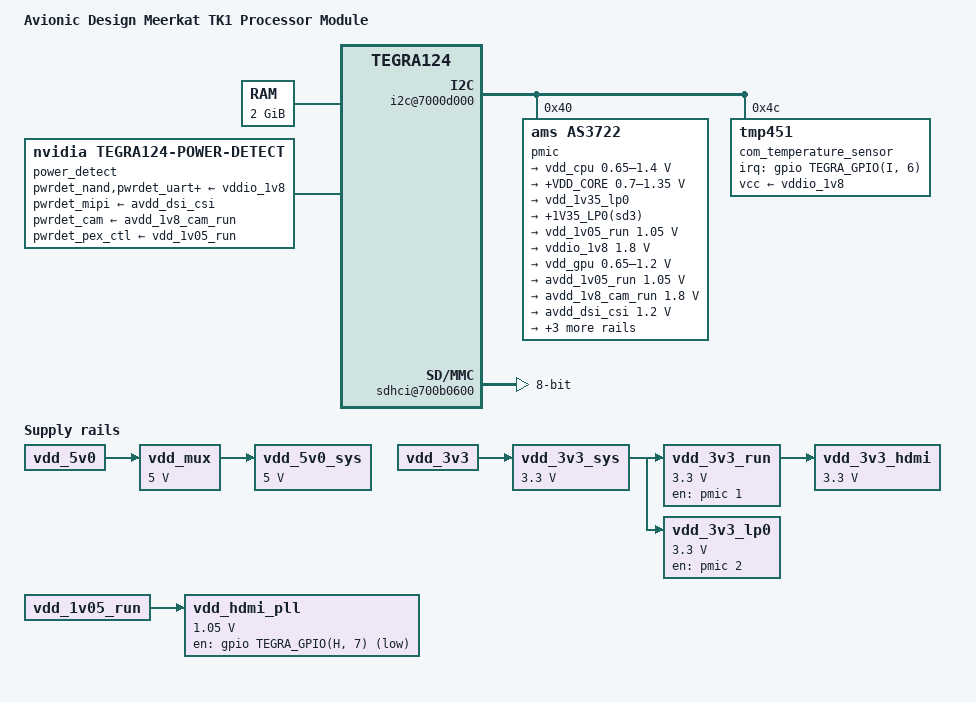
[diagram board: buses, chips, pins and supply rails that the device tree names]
#include <dt-bindings/pinctrl/pinctrl-tegra.h>
#include <dt-bindings/display/tegra-dc.h>
#include <dt-bindings/thermal/thermal.h>
#include <dt-bindings/usb/tegra-ehci.h>
#include <dt-bindings/usb/tegra-xhci.h>
#include <dt-bindings/pci/tegra-pcie.h>
#include <dt-bindings/mfd/as3722.h>
#include "tegra124.dtsi"

/ {
	model = "Avionic Design Meerkat TK1 Processor Module";
	compatible = "ad,meerkat", "nvidia,tegra124";

	aliases {
		rtc0 = "/i2c@7000d000/pmic@40";
		rtc1 = "/rtc@7000e000";
	};

	memory {
		device_type = "memory";
		reg = <0x0 0x80000000 0x0 0x80000000>;
	};

	psci {
		status = "disabled";
	};

	pmu {
		status = "okay";
	};

	pinmux {
		pinctrl-names = "default";
		pinctrl-0 = <&pinmux_default>;

		pinmux_default: common {
			dap_mclk1_pw4 {
				nvidia,pins = "dap_mclk1_pw4";
				nvidia,function = "extperiph1";
				nvidia,enable-input = <TEGRA_PIN_DISABLE>;
				nvidia,pull = <TEGRA_PIN_PULL_NONE>;
				nvidia,tristate = <TEGRA_PIN_DISABLE>;
			};

			dap_mclk1_req_pee2 {
				nvidia,pins = "dap_mclk1_req_pee2";
				nvidia,function = "sata";
				nvidia,enable-input = <TEGRA_PIN_DISABLE>;
				nvidia,pull = <TEGRA_PIN_PULL_NONE>;
				nvidia,tristate = <TEGRA_PIN_DISABLE>;
			};

			dap1_din_pn1 {
				nvidia,pins = "dap1_din_pn1";
				nvidia,function = "i2s0";
				nvidia,enable-input = <TEGRA_PIN_ENABLE>;
				nvidia,pull = <TEGRA_PIN_PULL_DOWN>;
				nvidia,tristate = <TEGRA_PIN_ENABLE>;
			};

			dap1_dout_pn2 {
				nvidia,pins = "dap1_dout_pn2";
				nvidia,function = "sata";
				nvidia,enable-input = <TEGRA_PIN_DISABLE>;
				nvidia,pull = <TEGRA_PIN_PULL_NONE>;
				nvidia,tristate = <TEGRA_PIN_DISABLE>;
			};

			dap1_fs_pn0 {
				nvidia,pins = "dap1_fs_pn0";
				nvidia,function = "i2s0";
				nvidia,enable-input = <TEGRA_PIN_ENABLE>;
				nvidia,pull = <TEGRA_PIN_PULL_DOWN>;
				nvidia,tristate = <TEGRA_PIN_ENABLE>;
			};

			dap1_sclk_pn3 {
				nvidia,pins = "dap1_sclk_pn3";
				nvidia,function = "i2s0";
				nvidia,enable-input = <TEGRA_PIN_ENABLE>;
				nvidia,pull = <TEGRA_PIN_PULL_DOWN>;
				nvidia,tristate = <TEGRA_PIN_ENABLE>;
			};

			dap2_din_pa4 {
				nvidia,pins = "dap2_din_pa4";
				nvidia,function = "i2s1";
				nvidia,enable-input = <TEGRA_PIN_ENABLE>;
				nvidia,pull = <TEGRA_PIN_PULL_NONE>;
				nvidia,tristate = <TEGRA_PIN_ENABLE>;
			};

			dap2_dout_pa5 {
				nvidia,pins = "dap2_dout_pa5";
				nvidia,function = "i2s1";
				nvidia,enable-input = <TEGRA_PIN_ENABLE>;
				nvidia,pull = <TEGRA_PIN_PULL_NONE>;
				nvidia,tristate = <TEGRA_PIN_ENABLE>;
			};

			dap2_fs_pa2 {
				nvidia,pins = "dap2_fs_pa2";
				nvidia,function = "i2s1";
				nvidia,enable-input = <TEGRA_PIN_ENABLE>;
				nvidia,pull = <TEGRA_PIN_PULL_NONE>;
				nvidia,tristate = <TEGRA_PIN_ENABLE>;
			};

			dap2_sclk_pa3 {
				nvidia,pins = "dap2_sclk_pa3";
				nvidia,function = "i2s1";
				nvidia,enable-input = <TEGRA_PIN_ENABLE>;
				nvidia,pull = <TEGRA_PIN_PULL_NONE>;
				nvidia,tristate = <TEGRA_PIN_ENABLE>;
			};

			dvfs_pwm_px0 {
				nvidia,pins = "dvfs_pwm_px0";
				nvidia,function = "cldvfs";
				nvidia,enable-input = <TEGRA_PIN_DISABLE>;
				nvidia,pull = <TEGRA_PIN_PULL_NONE>;
				nvidia,tristate = <TEGRA_PIN_DISABLE>;
			};

			dvfs_clk_px2 {
				nvidia,pins = "dvfs_clk_px2";
				nvidia,function = "cldvfs";
				nvidia,enable-input = <TEGRA_PIN_DISABLE>;
				nvidia,pull = <TEGRA_PIN_PULL_NONE>;
				nvidia,tristate = <TEGRA_PIN_DISABLE>;
			};

			ulpi_clk_py0 {
				nvidia,pins = "ulpi_clk_py0";
				nvidia,function = "spi1";
				nvidia,enable-input = <TEGRA_PIN_DISABLE>;
				nvidia,pull = <TEGRA_PIN_PULL_NONE>;
				nvidia,tristate = <TEGRA_PIN_DISABLE>;
			};

			ulpi_dir_py1 {
				nvidia,pins = "ulpi_dir_py1";
				nvidia,function = "spi1";
				nvidia,enable-input = <TEGRA_PIN_ENABLE>;
				nvidia,pull = <TEGRA_PIN_PULL_NONE>;
				nvidia,tristate = <TEGRA_PIN_DISABLE>;
			};

			ulpi_nxt_py2 {
				nvidia,pins = "ulpi_nxt_py2";
				nvidia,function = "spi1";
				nvidia,enable-input = <TEGRA_PIN_DISABLE>;
				nvidia,pull = <TEGRA_PIN_PULL_NONE>;
				nvidia,tristate = <TEGRA_PIN_DISABLE>;
			};

			ulpi_stp_py3 {
				nvidia,pins = "ulpi_stp_py3";
				nvidia,function = "spi1";
				nvidia,enable-input = <TEGRA_PIN_DISABLE>;
				nvidia,pull = <TEGRA_PIN_PULL_UP>;
				nvidia,tristate = <TEGRA_PIN_DISABLE>;
			};

			cam_i2c_scl_pbb1 {
				nvidia,pins = "cam_i2c_scl_pbb1";
				nvidia,function = "i2c3";
				nvidia,enable-input = <TEGRA_PIN_ENABLE>;
				nvidia,pull = <TEGRA_PIN_PULL_NONE>;
				nvidia,tristate = <TEGRA_PIN_DISABLE>;
				nvidia,lock = <TEGRA_PIN_DISABLE>;
				nvidia,open-drain = <TEGRA_PIN_ENABLE>;
			};

			cam_i2c_sda_pbb2 {
				nvidia,pins = "cam_i2c_sda_pbb2";
				nvidia,function = "i2c3";
				nvidia,enable-input = <TEGRA_PIN_ENABLE>;
				nvidia,pull = <TEGRA_PIN_PULL_NONE>;
				nvidia,tristate = <TEGRA_PIN_DISABLE>;
				nvidia,lock = <TEGRA_PIN_DISABLE>;
				nvidia,open-drain = <TEGRA_PIN_ENABLE>;
			};

			cam_mclk_pcc0 {
				nvidia,pins = "cam_mclk_pcc0";
				nvidia,function = "vi_alt3";
				nvidia,enable-input = <TEGRA_PIN_DISABLE>;
				nvidia,pull = <TEGRA_PIN_PULL_NONE>;
				nvidia,tristate = <TEGRA_PIN_DISABLE>;
			};

			pbb0 {
				nvidia,pins = "pbb0";
				nvidia,function = "vimclk2_alt";
				nvidia,enable-input = <TEGRA_PIN_DISABLE>;
				nvidia,pull = <TEGRA_PIN_PULL_NONE>;
				nvidia,tristate = <TEGRA_PIN_DISABLE>;
			};

			pbb4 {
				nvidia,pins = "pbb4";
				nvidia,function = "vgp4";
				nvidia,enable-input = <TEGRA_PIN_DISABLE>;
				nvidia,pull = <TEGRA_PIN_PULL_NONE>;
				nvidia,tristate = <TEGRA_PIN_DISABLE>;
			};

			gen2_i2c_scl_pt5 {
				nvidia,pins = "gen2_i2c_scl_pt5";
				nvidia,function = "i2c2";
				nvidia,enable-input = <TEGRA_PIN_ENABLE>;
				nvidia,pull = <TEGRA_PIN_PULL_NONE>;
				nvidia,tristate = <TEGRA_PIN_DISABLE>;
				nvidia,lock = <TEGRA_PIN_DISABLE>;
				nvidia,open-drain = <TEGRA_PIN_ENABLE>;
			};

			gen2_i2c_sda_pt6 {
				nvidia,pins = "gen2_i2c_sda_pt6";
				nvidia,function = "i2c2";
				nvidia,enable-input = <TEGRA_PIN_ENABLE>;
				nvidia,pull = <TEGRA_PIN_PULL_NONE>;
				nvidia,tristate = <TEGRA_PIN_DISABLE>;
				nvidia,lock = <TEGRA_PIN_DISABLE>;
				nvidia,open-drain = <TEGRA_PIN_ENABLE>;
			};

			pj7 {
				nvidia,pins = "pj7";
				nvidia,function = "uartd";
				nvidia,enable-input = <TEGRA_PIN_DISABLE>;
				nvidia,pull = <TEGRA_PIN_PULL_NONE>;
				nvidia,tristate = <TEGRA_PIN_DISABLE>;
			};

			pb0 {
				nvidia,pins = "pb0";
				nvidia,function = "uartd";
				nvidia,enable-input = <TEGRA_PIN_ENABLE>;
				nvidia,pull = <TEGRA_PIN_PULL_UP>;
				nvidia,tristate = <TEGRA_PIN_DISABLE>;
			};

			pb1 {
				nvidia,pins = "pb1";
				nvidia,function = "uartd";
				nvidia,enable-input = <TEGRA_PIN_ENABLE>;
				nvidia,pull = <TEGRA_PIN_PULL_UP>;
				nvidia,tristate = <TEGRA_PIN_DISABLE>;
			};

			pk7 {
				nvidia,pins = "pk7";
				nvidia,function = "uartd";
				nvidia,enable-input = <TEGRA_PIN_DISABLE>;
				nvidia,pull = <TEGRA_PIN_PULL_NONE>;
				nvidia,tristate = <TEGRA_PIN_DISABLE>;
			};

			pg4 {
				nvidia,pins = "pg4";
				nvidia,function = "spi4";
				nvidia,enable-input = <TEGRA_PIN_DISABLE>;
				nvidia,pull = <TEGRA_PIN_PULL_UP>;
				nvidia,tristate = <TEGRA_PIN_ENABLE>;
			};

			pg5 {
				nvidia,pins = "pg5";
				nvidia,function = "spi4";
				nvidia,enable-input = <TEGRA_PIN_DISABLE>;
				nvidia,pull = <TEGRA_PIN_PULL_NONE>;
				nvidia,tristate = <TEGRA_PIN_DISABLE>;
			};

			pg6 {
				nvidia,pins = "pg6";
				nvidia,function = "spi4";
				nvidia,enable-input = <TEGRA_PIN_DISABLE>;
				nvidia,pull = <TEGRA_PIN_PULL_NONE>;
				nvidia,tristate = <TEGRA_PIN_DISABLE>;
			};

			pg7 {
				nvidia,pins = "pg7";
				nvidia,function = "spi4";
				nvidia,enable-input = <TEGRA_PIN_ENABLE>;
				nvidia,pull = <TEGRA_PIN_PULL_NONE>;
				nvidia,tristate = <TEGRA_PIN_DISABLE>;
			};

			pi3 {
				nvidia,pins = "pi3";
				nvidia,function = "spi4";
				nvidia,enable-input = <TEGRA_PIN_DISABLE>;
				nvidia,pull = <TEGRA_PIN_PULL_UP>;
				nvidia,tristate = <TEGRA_PIN_DISABLE>;
			};

			ph1 {
				nvidia,pins = "ph1";
				nvidia,function = "pwm1";
				nvidia,enable-input = <TEGRA_PIN_DISABLE>;
				nvidia,pull = <TEGRA_PIN_PULL_NONE>;
				nvidia,tristate = <TEGRA_PIN_DISABLE>;
			};

			pk0 {
				nvidia,pins = "pk0";
				nvidia,function = "soc";
				nvidia,enable-input = <TEGRA_PIN_ENABLE>;
				nvidia,pull = <TEGRA_PIN_PULL_UP>;
				nvidia,tristate = <TEGRA_PIN_ENABLE>;
			};

			kb_row15_ps7 {
				nvidia,pins = "kb_row15_ps7";
				nvidia,function = "soc";
				nvidia,enable-input = <TEGRA_PIN_ENABLE>;
				nvidia,pull = <TEGRA_PIN_PULL_UP>;
				nvidia,tristate = <TEGRA_PIN_DISABLE>;
			};

			clk_32k_out_pa0 {
				nvidia,pins = "clk_32k_out_pa0";
				nvidia,function = "soc";
				nvidia,enable-input = <TEGRA_PIN_ENABLE>;
				nvidia,pull = <TEGRA_PIN_PULL_UP>;
				nvidia,tristate = <TEGRA_PIN_DISABLE>;
			};

			pex_l0_clkreq_n_pdd2 {
				nvidia,pins = "pex_l0_clkreq_n_pdd2";
				nvidia,function = "pe0";
				nvidia,enable-input = <TEGRA_PIN_ENABLE>;
				nvidia,pull = <TEGRA_PIN_PULL_UP>;
				nvidia,tristate = <TEGRA_PIN_DISABLE>;
			};

			pex_l0_rst_n_pdd1 {
				nvidia,pins = "pex_l0_rst_n_pdd1";
				nvidia,function = "pe0";
				nvidia,enable-input = <TEGRA_PIN_DISABLE>;
				nvidia,pull = <TEGRA_PIN_PULL_NONE>;
				nvidia,tristate = <TEGRA_PIN_DISABLE>;
			};

			pex_l1_rst_n_pdd5 {
				nvidia,pins = "pex_l1_rst_n_pdd5";
				nvidia,function = "pe1";
				nvidia,enable-input = <TEGRA_PIN_DISABLE>;
				nvidia,pull = <TEGRA_PIN_PULL_NONE>;
				nvidia,tristate = <TEGRA_PIN_DISABLE>;
			};

			pex_l1_clkreq_n_pdd6 {
				nvidia,pins = "pex_l1_clkreq_n_pdd6";
				nvidia,function = "pe1";
				nvidia,enable-input = <TEGRA_PIN_ENABLE>;
				nvidia,pull = <TEGRA_PIN_PULL_UP>;
				nvidia,tristate = <TEGRA_PIN_DISABLE>;
			};

			pex_wake_n_pdd3 {
				nvidia,pins = "pex_wake_n_pdd3";
				nvidia,function = "pe";
				nvidia,enable-input = <TEGRA_PIN_ENABLE>;
				nvidia,pull = <TEGRA_PIN_PULL_UP>;
				nvidia,tristate = <TEGRA_PIN_DISABLE>;
			};

			sdmmc1_clk_pz0 {
				nvidia,pins = "sdmmc1_clk_pz0";
				nvidia,function = "sdmmc1";
				nvidia,enable-input = <TEGRA_PIN_ENABLE>;
				nvidia,pull = <TEGRA_PIN_PULL_NONE>;
				nvidia,tristate = <TEGRA_PIN_ENABLE>;
			};

			sdmmc1_cmd_pz1 {
				nvidia,pins = "sdmmc1_cmd_pz1";
				nvidia,function = "sdmmc1";
				nvidia,enable-input = <TEGRA_PIN_ENABLE>;
				nvidia,pull = <TEGRA_PIN_PULL_UP>;
				nvidia,tristate = <TEGRA_PIN_ENABLE>;
			};

			sdmmc1_dat0_py7 {
				nvidia,pins = "sdmmc1_dat0_py7";
				nvidia,function = "sdmmc1";
				nvidia,enable-input = <TEGRA_PIN_ENABLE>;
				nvidia,pull = <TEGRA_PIN_PULL_UP>;
				nvidia,tristate = <TEGRA_PIN_ENABLE>;
			};

			sdmmc1_dat1_py6 {
				nvidia,pins = "sdmmc1_dat1_py6";
				nvidia,function = "sdmmc1";
				nvidia,enable-input = <TEGRA_PIN_ENABLE>;
				nvidia,pull = <TEGRA_PIN_PULL_UP>;
				nvidia,tristate = <TEGRA_PIN_ENABLE>;
			};

			sdmmc1_dat2_py5 {
				nvidia,pins = "sdmmc1_dat2_py5";
				nvidia,function = "sdmmc1";
				nvidia,enable-input = <TEGRA_PIN_ENABLE>;
				nvidia,pull = <TEGRA_PIN_PULL_UP>;
				nvidia,tristate = <TEGRA_PIN_ENABLE>;
			};

			sdmmc1_dat3_py4 {
				nvidia,pins = "sdmmc1_dat3_py4";
				nvidia,function = "sdmmc1";
				nvidia,enable-input = <TEGRA_PIN_ENABLE>;
				nvidia,pull = <TEGRA_PIN_PULL_UP>;
				nvidia,tristate = <TEGRA_PIN_ENABLE>;
			};

			sdmmc3_clk_pa6 {
				nvidia,pins = "sdmmc3_clk_pa6";
				nvidia,function = "sdmmc3";
				nvidia,enable-input = <TEGRA_PIN_DISABLE>;
				nvidia,pull = <TEGRA_PIN_PULL_NONE>;
				nvidia,tristate = <TEGRA_PIN_DISABLE>;
			};

			sdmmc3_cmd_pa7 {
				nvidia,pins = "sdmmc3_cmd_pa7";
				nvidia,function = "sdmmc3";
				nvidia,enable-input = <TEGRA_PIN_ENABLE>;
				nvidia,pull = <TEGRA_PIN_PULL_UP>;
				nvidia,tristate = <TEGRA_PIN_DISABLE>;
			};

			sdmmc3_dat0_pb7 {
				nvidia,pins = "sdmmc3_dat0_pb7";
				nvidia,function = "sdmmc3";
				nvidia,enable-input = <TEGRA_PIN_ENABLE>;
				nvidia,pull = <TEGRA_PIN_PULL_UP>;
				nvidia,tristate = <TEGRA_PIN_DISABLE>;
			};

			sdmmc3_dat1_pb6 {
				nvidia,pins = "sdmmc3_dat1_pb6";
				nvidia,function = "sdmmc3";
				nvidia,enable-input = <TEGRA_PIN_ENABLE>;
				nvidia,pull = <TEGRA_PIN_PULL_UP>;
				nvidia,tristate = <TEGRA_PIN_DISABLE>;
			};

			sdmmc3_dat2_pb5 {
				nvidia,pins = "sdmmc3_dat2_pb5";
				nvidia,function = "sdmmc3";
				nvidia,enable-input = <TEGRA_PIN_ENABLE>;
				nvidia,pull = <TEGRA_PIN_PULL_UP>;
				nvidia,tristate = <TEGRA_PIN_DISABLE>;
			};

			sdmmc3_dat3_pb4 {
				nvidia,pins = "sdmmc3_dat3_pb4";
				nvidia,function = "sdmmc3";
				nvidia,enable-input = <TEGRA_PIN_ENABLE>;
				nvidia,pull = <TEGRA_PIN_PULL_UP>;
				nvidia,tristate = <TEGRA_PIN_DISABLE>;
			};

			sdmmc3_clk_lb_out_pee4 {
				nvidia,pins = "sdmmc3_clk_lb_out_pee4";
				nvidia,function = "sdmmc3";
				nvidia,enable-input = <TEGRA_PIN_ENABLE>;
				nvidia,pull = <TEGRA_PIN_PULL_UP>;
				nvidia,tristate = <TEGRA_PIN_DISABLE>;
			};

			sdmmc3_clk_lb_in_pee5 {
				nvidia,pins = "sdmmc3_clk_lb_in_pee5";
				nvidia,function = "sdmmc3";
				nvidia,enable-input = <TEGRA_PIN_ENABLE>;
				nvidia,pull = <TEGRA_PIN_PULL_UP>;
				nvidia,tristate = <TEGRA_PIN_DISABLE>;
			};

			kb_col4_pq4 {
				nvidia,pins = "kb_col4_pq4";
				nvidia,function = "sdmmc3";
				nvidia,enable-input = <TEGRA_PIN_ENABLE>;
				nvidia,pull = <TEGRA_PIN_PULL_UP>;
				nvidia,tristate = <TEGRA_PIN_DISABLE>;
			};

			sdmmc3_cd_n_pv2 {
				nvidia,pins = "sdmmc3_cd_n_pv2";
				nvidia,function = "sdmmc3";
				nvidia,enable-input = <TEGRA_PIN_ENABLE>;
				nvidia,pull = <TEGRA_PIN_PULL_UP>;
				nvidia,tristate = <TEGRA_PIN_DISABLE>;
			};

			sdmmc4_clk_pcc4 {
				nvidia,pins = "sdmmc4_clk_pcc4";
				nvidia,function = "sdmmc4";
				nvidia,enable-input = <TEGRA_PIN_ENABLE>;
				nvidia,pull = <TEGRA_PIN_PULL_NONE>;
				nvidia,tristate = <TEGRA_PIN_DISABLE>;
			};

			sdmmc4_cmd_pt7 {
				nvidia,pins = "sdmmc4_cmd_pt7";
				nvidia,function = "sdmmc4";
				nvidia,enable-input = <TEGRA_PIN_ENABLE>;
				nvidia,pull = <TEGRA_PIN_PULL_UP>;
				nvidia,tristate = <TEGRA_PIN_DISABLE>;
			};

			sdmmc4_dat0_paa0 {
				nvidia,pins = "sdmmc4_dat0_paa0";
				nvidia,function = "sdmmc4";
				nvidia,enable-input = <TEGRA_PIN_ENABLE>;
				nvidia,pull = <TEGRA_PIN_PULL_UP>;
				nvidia,tristate = <TEGRA_PIN_DISABLE>;
			};

			sdmmc4_dat1_paa1 {
				nvidia,pins = "sdmmc4_dat1_paa1";
				nvidia,function = "sdmmc4";
				nvidia,enable-input = <TEGRA_PIN_ENABLE>;
				nvidia,pull = <TEGRA_PIN_PULL_UP>;
				nvidia,tristate = <TEGRA_PIN_DISABLE>;
			};

			sdmmc4_dat2_paa2 {
				nvidia,pins = "sdmmc4_dat2_paa2";
				nvidia,function = "sdmmc4";
				nvidia,enable-input = <TEGRA_PIN_ENABLE>;
				nvidia,pull = <TEGRA_PIN_PULL_UP>;
				nvidia,tristate = <TEGRA_PIN_DISABLE>;
			};

			sdmmc4_dat3_paa3 {
				nvidia,pins = "sdmmc4_dat3_paa3";
				nvidia,function = "sdmmc4";
				nvidia,enable-input = <TEGRA_PIN_ENABLE>;
				nvidia,pull = <TEGRA_PIN_PULL_UP>;
				nvidia,tristate = <TEGRA_PIN_DISABLE>;
			};

			sdmmc4_dat4_paa4 {
				nvidia,pins = "sdmmc4_dat4_paa4";
				nvidia,function = "sdmmc4";
				nvidia,enable-input = <TEGRA_PIN_ENABLE>;
				nvidia,pull = <TEGRA_PIN_PULL_UP>;
				nvidia,tristate = <TEGRA_PIN_DISABLE>;
			};

			sdmmc4_dat5_paa5 {
				nvidia,pins = "sdmmc4_dat5_paa5";
				nvidia,function = "sdmmc4";
				nvidia,enable-input = <TEGRA_PIN_ENABLE>;
				nvidia,pull = <TEGRA_PIN_PULL_UP>;
				nvidia,tristate = <TEGRA_PIN_DISABLE>;
			};

			sdmmc4_dat6_paa6 {
				nvidia,pins = "sdmmc4_dat6_paa6";
				nvidia,function = "sdmmc4";
				nvidia,enable-input = <TEGRA_PIN_ENABLE>;
				nvidia,pull = <TEGRA_PIN_PULL_UP>;
				nvidia,tristate = <TEGRA_PIN_DISABLE>;
			};

			sdmmc4_dat7_paa7 {
				nvidia,pins = "sdmmc4_dat7_paa7";
				nvidia,function = "sdmmc4";
				nvidia,enable-input = <TEGRA_PIN_ENABLE>;
				nvidia,pull = <TEGRA_PIN_PULL_UP>;
				nvidia,tristate = <TEGRA_PIN_DISABLE>;
			};

			kb_row10_ps2 {
				nvidia,pins = "kb_row10_ps2";
				nvidia,function = "uarta";
				nvidia,enable-input = <TEGRA_PIN_ENABLE>;
				nvidia,pull = <TEGRA_PIN_PULL_UP>;
				nvidia,tristate = <TEGRA_PIN_DISABLE>;
			};

			kb_row9_ps1 {
				nvidia,pins = "kb_row9_ps1";
				nvidia,function = "uarta";
				nvidia,enable-input = <TEGRA_PIN_DISABLE>;
				nvidia,pull = <TEGRA_PIN_PULL_NONE>;
				nvidia,tristate = <TEGRA_PIN_DISABLE>;
			};

			kb_row3_pr3 {
				nvidia,pins = "kb_row3_pr3";
				nvidia,function = "sys";
				nvidia,enable-input = <TEGRA_PIN_DISABLE>;
				nvidia,pull = <TEGRA_PIN_PULL_NONE>;
				nvidia,tristate = <TEGRA_PIN_ENABLE>;
			};

			kb_row6_pr6 {
				nvidia,pins = "kb_row6_pr6";
				nvidia,function = "displaya_alt";
				nvidia,enable-input = <TEGRA_PIN_ENABLE>;
				nvidia,pull = <TEGRA_PIN_PULL_DOWN>;
				nvidia,tristate = <TEGRA_PIN_DISABLE>;
			};

			pwr_i2c_scl_pz6 {
				nvidia,pins = "pwr_i2c_scl_pz6";
				nvidia,function = "i2cpwr";
				nvidia,enable-input = <TEGRA_PIN_ENABLE>;
				nvidia,pull = <TEGRA_PIN_PULL_NONE>;
				nvidia,tristate = <TEGRA_PIN_DISABLE>;
				nvidia,open-drain = <TEGRA_PIN_ENABLE>;
			};

			pwr_i2c_sda_pz7 {
				nvidia,pins = "pwr_i2c_sda_pz7";
				nvidia,function = "i2cpwr";
				nvidia,enable-input = <TEGRA_PIN_ENABLE>;
				nvidia,pull = <TEGRA_PIN_PULL_NONE>;
				nvidia,tristate = <TEGRA_PIN_DISABLE>;
				nvidia,open-drain = <TEGRA_PIN_ENABLE>;
			};

			jtag_rtck {
				nvidia,pins = "jtag_rtck";
				nvidia,function = "rtck";
				nvidia,enable-input = <TEGRA_PIN_DISABLE>;
				nvidia,pull = <TEGRA_PIN_PULL_UP>;
				nvidia,tristate = <TEGRA_PIN_DISABLE>;
			};

			clk_32k_in {
				nvidia,pins = "clk_32k_in";
				nvidia,function = "clk";
				nvidia,enable-input = <TEGRA_PIN_ENABLE>;
				nvidia,pull = <TEGRA_PIN_PULL_NONE>;
				nvidia,tristate = <TEGRA_PIN_DISABLE>;
			};

			clk2_out_pw5 {
				nvidia,pins = "clk2_out_pw5";
				nvidia,function = "extperiph2";
				nvidia,enable-input = <TEGRA_PIN_DISABLE>;
				nvidia,pull = <TEGRA_PIN_PULL_NONE>;
				nvidia,tristate = <TEGRA_PIN_DISABLE>;
			};

			core_pwr_req {
				nvidia,pins = "core_pwr_req";
				nvidia,function = "pwron";
				nvidia,enable-input = <TEGRA_PIN_DISABLE>;
				nvidia,pull = <TEGRA_PIN_PULL_NONE>;
				nvidia,tristate = <TEGRA_PIN_DISABLE>;
			};

			cpu_pwr_req {
				nvidia,pins = "cpu_pwr_req";
				nvidia,function = "cpu";
				nvidia,enable-input = <TEGRA_PIN_DISABLE>;
				nvidia,pull = <TEGRA_PIN_PULL_NONE>;
				nvidia,tristate = <TEGRA_PIN_DISABLE>;
			};

			pwr_int_n {
				nvidia,pins = "pwr_int_n";
				nvidia,function = "pmi";
				nvidia,enable-input = <TEGRA_PIN_ENABLE>;
				nvidia,pull = <TEGRA_PIN_PULL_UP>;
				nvidia,tristate = <TEGRA_PIN_DISABLE>;
			};

			reset_out_n {
				nvidia,pins = "reset_out_n";
				nvidia,function = "reset_out_n";
				nvidia,enable-input = <TEGRA_PIN_DISABLE>;
				nvidia,pull = <TEGRA_PIN_PULL_NONE>;
				nvidia,tristate = <TEGRA_PIN_DISABLE>;
			};

			clk3_out_pee0 {
				nvidia,pins = "clk3_out_pee0";
				nvidia,function = "extperiph3";
				nvidia,enable-input = <TEGRA_PIN_DISABLE>;
				nvidia,pull = <TEGRA_PIN_PULL_NONE>;
				nvidia,tristate = <TEGRA_PIN_DISABLE>;
			};

			dp_hpd_pff0 {
				nvidia,pins = "dp_hpd_pff0";
				nvidia,function = "dp";
				nvidia,enable-input = <TEGRA_PIN_ENABLE>;
				nvidia,pull = <TEGRA_PIN_PULL_UP>;
				nvidia,tristate = <TEGRA_PIN_DISABLE>;
			};

			dap4_din_pp5 {
				nvidia,pins = "dap4_din_pp5";
				nvidia,function = "i2s3";
				nvidia,enable-input = <TEGRA_PIN_ENABLE>;
				nvidia,pull = <TEGRA_PIN_PULL_DOWN>;
				nvidia,tristate = <TEGRA_PIN_ENABLE>;
			};

			dap4_dout_pp6 {
				nvidia,pins = "dap4_dout_pp6";
				nvidia,function = "i2s3";
				nvidia,enable-input = <TEGRA_PIN_ENABLE>;
				nvidia,pull = <TEGRA_PIN_PULL_DOWN>;
				nvidia,tristate = <TEGRA_PIN_ENABLE>;
			};

			dap4_fs_pp4 {
				nvidia,pins = "dap4_fs_pp4";
				nvidia,function = "i2s3";
				nvidia,enable-input = <TEGRA_PIN_ENABLE>;
				nvidia,pull = <TEGRA_PIN_PULL_DOWN>;
				nvidia,tristate = <TEGRA_PIN_ENABLE>;
			};

			dap4_sclk_pp7 {
				nvidia,pins = "dap4_sclk_pp7";
				nvidia,function = "i2s3";
				nvidia,enable-input = <TEGRA_PIN_ENABLE>;
				nvidia,pull = <TEGRA_PIN_PULL_NONE>;
				nvidia,tristate = <TEGRA_PIN_ENABLE>;
			};

			gen1_i2c_sda_pc5 {
				nvidia,pins = "gen1_i2c_sda_pc5";
				nvidia,function = "i2c1";
				nvidia,enable-input = <TEGRA_PIN_ENABLE>;
				nvidia,pull = <TEGRA_PIN_PULL_NONE>;
				nvidia,tristate = <TEGRA_PIN_DISABLE>;
				nvidia,lock = <TEGRA_PIN_DISABLE>;
				nvidia,open-drain = <TEGRA_PIN_ENABLE>;
			};

			gen1_i2c_scl_pc4 {
				nvidia,pins = "gen1_i2c_scl_pc4";
				nvidia,function = "i2c1";
				nvidia,enable-input = <TEGRA_PIN_ENABLE>;
				nvidia,pull = <TEGRA_PIN_PULL_NONE>;
				nvidia,tristate = <TEGRA_PIN_DISABLE>;
				nvidia,lock = <TEGRA_PIN_DISABLE>;
				nvidia,open-drain = <TEGRA_PIN_ENABLE>;
			};

			uart2_cts_n_pj5 {
				nvidia,pins = "uart2_cts_n_pj5";
				nvidia,function = "uartb";
				nvidia,enable-input = <TEGRA_PIN_ENABLE>;
				nvidia,pull = <TEGRA_PIN_PULL_UP>;
				nvidia,tristate = <TEGRA_PIN_DISABLE>;
			};

			uart2_rts_n_pj6 {
				nvidia,pins = "uart2_rts_n_pj6";
				nvidia,function = "uartb";
				nvidia,enable-input = <TEGRA_PIN_DISABLE>;
				nvidia,pull = <TEGRA_PIN_PULL_UP>;
				nvidia,tristate = <TEGRA_PIN_DISABLE>;
			};

			uart2_rxd_pc3 {
				nvidia,pins = "uart2_rxd_pc3";
				nvidia,function = "irda";
				nvidia,enable-input = <TEGRA_PIN_ENABLE>;
				nvidia,pull = <TEGRA_PIN_PULL_UP>;
				nvidia,tristate = <TEGRA_PIN_DISABLE>;
			};

			uart2_txd_pc2 {
				nvidia,pins = "uart2_txd_pc2";
				nvidia,function = "irda";
				nvidia,enable-input = <TEGRA_PIN_DISABLE>;
				nvidia,pull = <TEGRA_PIN_PULL_UP>;
				nvidia,tristate = <TEGRA_PIN_DISABLE>;
			};

			uart3_cts_n_pa1 {
				nvidia,pins = "uart3_cts_n_pa1";
				nvidia,function = "uartc";
				nvidia,enable-input = <TEGRA_PIN_ENABLE>;
				nvidia,pull = <TEGRA_PIN_PULL_UP>;
				nvidia,tristate = <TEGRA_PIN_ENABLE>;
			};

			uart3_rts_n_pc0 {
				nvidia,pins = "uart3_rts_n_pc0";
				nvidia,function = "uartc";
				nvidia,enable-input = <TEGRA_PIN_DISABLE>;
				nvidia,pull = <TEGRA_PIN_PULL_UP>;
				nvidia,tristate = <TEGRA_PIN_ENABLE>;
			};

			uart3_rxd_pw7 {
				nvidia,pins = "uart3_rxd_pw7";
				nvidia,function = "uartc";
				nvidia,enable-input = <TEGRA_PIN_ENABLE>;
				nvidia,pull = <TEGRA_PIN_PULL_UP>;
				nvidia,tristate = <TEGRA_PIN_ENABLE>;
			};

			uart3_txd_pw6 {
				nvidia,pins = "uart3_txd_pw6";
				nvidia,function = "uartc";
				nvidia,enable-input = <TEGRA_PIN_DISABLE>;
				nvidia,pull = <TEGRA_PIN_PULL_UP>;
				nvidia,tristate = <TEGRA_PIN_ENABLE>;
			};

			hdmi_cec_pee3 {
				nvidia,pins = "hdmi_cec_pee3";
				nvidia,function = "cec";
				nvidia,enable-input = <TEGRA_PIN_ENABLE>;
				nvidia,pull = <TEGRA_PIN_PULL_NONE>;
				nvidia,tristate = <TEGRA_PIN_DISABLE>;
				nvidia,open-drain = <TEGRA_PIN_ENABLE>;
			};

			ddc_scl_pv4 {
				nvidia,pins = "ddc_scl_pv4";
				nvidia,function = "i2c4";
				nvidia,enable-input = <TEGRA_PIN_ENABLE>;
				nvidia,pull = <TEGRA_PIN_PULL_NONE>;
				nvidia,tristate = <TEGRA_PIN_DISABLE>;
			};

			ddc_sda_pv5 {
				nvidia,pins = "ddc_sda_pv5";
				nvidia,function = "i2c4";
				nvidia,enable-input = <TEGRA_PIN_ENABLE>;
				nvidia,pull = <TEGRA_PIN_PULL_NONE>;
				nvidia,tristate = <TEGRA_PIN_DISABLE>;
			};

			usb_vbus_en0_pn4 {
				nvidia,pins = "usb_vbus_en0_pn4";
				nvidia,function = "usb";
				nvidia,enable-input = <TEGRA_PIN_ENABLE>;
				nvidia,pull = <TEGRA_PIN_PULL_UP>;
				nvidia,tristate = <TEGRA_PIN_DISABLE>;
				nvidia,lock = <TEGRA_PIN_DISABLE>;
				nvidia,open-drain = <TEGRA_PIN_ENABLE>;
			};

			usb_vbus_en1_pn5 {
				nvidia,pins = "usb_vbus_en1_pn5";
				nvidia,function = "usb";
				nvidia,enable-input = <TEGRA_PIN_ENABLE>;
				nvidia,pull = <TEGRA_PIN_PULL_UP>;
				nvidia,tristate = <TEGRA_PIN_DISABLE>;
				nvidia,lock = <TEGRA_PIN_DISABLE>;
				nvidia,open-drain = <TEGRA_PIN_ENABLE>;
			};

			usb_vbus_en2_pff1 {
				nvidia,pins = "usb_vbus_en2_pff1";
				nvidia,function = "usb";
				nvidia,enable-input = <TEGRA_PIN_ENABLE>;
				nvidia,pull = <TEGRA_PIN_PULL_UP>;
				nvidia,tristate = <TEGRA_PIN_DISABLE>;
				nvidia,lock = <TEGRA_PIN_DISABLE>;
				nvidia,open-drain = <TEGRA_PIN_ENABLE>;
			};

			gpio_x4_aud_px4 {
				nvidia,pins = "gpio_x4_aud_px4";
				nvidia,function = "safe";
				nvidia,enable-input = <TEGRA_PIN_DISABLE>;
				nvidia,pull = <TEGRA_PIN_PULL_NONE>;
				nvidia,tristate = <TEGRA_PIN_ENABLE>;
			};

			gpio_x5_aud_px5 {
				nvidia,pins = "gpio_x5_aud_px5";
				nvidia,function = "safe";
				nvidia,enable-input = <TEGRA_PIN_ENABLE>;
				nvidia,pull = <TEGRA_PIN_PULL_UP>;
				nvidia,tristate = <TEGRA_PIN_ENABLE>;
			};

			gpio_x6_aud_px6 {
				nvidia,pins = "gpio_x6_aud_px6";
				nvidia,function = "safe";
				nvidia,enable-input = <TEGRA_PIN_ENABLE>;
				nvidia,pull = <TEGRA_PIN_PULL_UP>;
				nvidia,tristate = <TEGRA_PIN_ENABLE>;
			};

			gpio_x7_aud_px7 {
				nvidia,pins = "gpio_x7_aud_px7";
				nvidia,function = "safe";
				nvidia,enable-input = <TEGRA_PIN_DISABLE>;
				nvidia,pull = <TEGRA_PIN_PULL_NONE>;
				nvidia,tristate = <TEGRA_PIN_ENABLE>;
			};

			gpio_w2_aud_pw2 {
				nvidia,pins = "gpio_w2_aud_pw2";
				nvidia,function = "safe";
				nvidia,enable-input = <TEGRA_PIN_ENABLE>;
				nvidia,pull = <TEGRA_PIN_PULL_UP>;
				nvidia,tristate = <TEGRA_PIN_ENABLE>;
			};

			gpio_w3_aud_pw3 {
				nvidia,pins = "gpio_w3_aud_pw3";
				nvidia,function = "safe";
				nvidia,enable-input = <TEGRA_PIN_ENABLE>;
				nvidia,pull = <TEGRA_PIN_PULL_UP>;
				nvidia,tristate = <TEGRA_PIN_ENABLE>;
			};

			gpio_x1_aud_px1 {
				nvidia,pins = "gpio_x1_aud_px1";
				nvidia,function = "safe";
				nvidia,enable-input = <TEGRA_PIN_DISABLE>;
				nvidia,pull = <TEGRA_PIN_PULL_NONE>;
				nvidia,tristate = <TEGRA_PIN_DISABLE>;
			};

			gpio_x3_aud_px3 {
				nvidia,pins = "gpio_x3_aud_px3";
				nvidia,function = "safe";
				nvidia,enable-input = <TEGRA_PIN_ENABLE>;
				nvidia,pull = <TEGRA_PIN_PULL_UP>;
				nvidia,tristate = <TEGRA_PIN_ENABLE>;
			};

			dap3_din_pp1 {
				nvidia,pins = "dap3_din_pp1";
				nvidia,function = "safe";
				nvidia,enable-input = <TEGRA_PIN_DISABLE>;
				nvidia,pull = <TEGRA_PIN_PULL_NONE>;
				nvidia,tristate = <TEGRA_PIN_ENABLE>;
			};

			dap3_dout_pp2 {
				nvidia,pins = "dap3_dout_pp2";
				nvidia,function = "safe";
				nvidia,enable-input = <TEGRA_PIN_DISABLE>;
				nvidia,pull = <TEGRA_PIN_PULL_NONE>;
				nvidia,tristate = <TEGRA_PIN_DISABLE>;
			};

			dap3_fs_pp0 {
				nvidia,pins = "dap3_fs_pp0";
				nvidia,function = "safe";
				nvidia,enable-input = <TEGRA_PIN_DISABLE>;
				nvidia,pull = <TEGRA_PIN_PULL_NONE>;
				nvidia,tristate = <TEGRA_PIN_ENABLE>;
			};

			pv0 {
				nvidia,pins = "pv0";
				nvidia,function = "safe";
				nvidia,enable-input = <TEGRA_PIN_ENABLE>;
				nvidia,pull = <TEGRA_PIN_PULL_UP>;
				nvidia,tristate = <TEGRA_PIN_ENABLE>;
			};

			pv1 {
				nvidia,pins = "pv1";
				nvidia,function = "safe";
				nvidia,enable-input = <TEGRA_PIN_ENABLE>;
				nvidia,pull = <TEGRA_PIN_PULL_UP>;
				nvidia,tristate = <TEGRA_PIN_ENABLE>;
			};

			ulpi_data0_po1 {
				nvidia,pins = "ulpi_data0_po1";
				nvidia,function = "safe";
				nvidia,enable-input = <TEGRA_PIN_ENABLE>;
				nvidia,pull = <TEGRA_PIN_PULL_UP>;
				nvidia,tristate = <TEGRA_PIN_DISABLE>;
			};

			ulpi_data1_po2 {
				nvidia,pins = "ulpi_data1_po2";
				nvidia,function = "safe";
				nvidia,enable-input = <TEGRA_PIN_ENABLE>;
				nvidia,pull = <TEGRA_PIN_PULL_UP>;
				nvidia,tristate = <TEGRA_PIN_ENABLE>;
			};

			ulpi_data2_po3 {
				nvidia,pins = "ulpi_data2_po3";
				nvidia,function = "safe";
				nvidia,enable-input = <TEGRA_PIN_ENABLE>;
				nvidia,pull = <TEGRA_PIN_PULL_UP>;
				nvidia,tristate = <TEGRA_PIN_ENABLE>;
			};

			pbb3 {
				nvidia,pins = "pbb3";
				nvidia,function = "safe";
				nvidia,enable-input = <TEGRA_PIN_DISABLE>;
				nvidia,pull = <TEGRA_PIN_PULL_NONE>;
				nvidia,tristate = <TEGRA_PIN_DISABLE>;
			};

			pbb5 {
				nvidia,pins = "pbb5";
				nvidia,function = "safe";
				nvidia,enable-input = <TEGRA_PIN_DISABLE>;
				nvidia,pull = <TEGRA_PIN_PULL_NONE>;
				nvidia,tristate = <TEGRA_PIN_DISABLE>;
			};

			pbb6 {
				nvidia,pins = "pbb6";
				nvidia,function = "safe";
				nvidia,enable-input = <TEGRA_PIN_DISABLE>;
				nvidia,pull = <TEGRA_PIN_PULL_NONE>;
				nvidia,tristate = <TEGRA_PIN_DISABLE>;
			};

			pbb7 {
				nvidia,pins = "pbb7";
				nvidia,function = "safe";
				nvidia,enable-input = <TEGRA_PIN_DISABLE>;
				nvidia,pull = <TEGRA_PIN_PULL_NONE>;
				nvidia,tristate = <TEGRA_PIN_DISABLE>;
			};

			pcc1 {
				nvidia,pins = "pcc1";
				nvidia,function = "safe";
				nvidia,enable-input = <TEGRA_PIN_ENABLE>;
				nvidia,pull = <TEGRA_PIN_PULL_DOWN>;
				nvidia,tristate = <TEGRA_PIN_DISABLE>;
			};

			pcc2 {
				nvidia,pins = "pcc2";
				nvidia,function = "safe";
				nvidia,enable-input = <TEGRA_PIN_ENABLE>;
				nvidia,pull = <TEGRA_PIN_PULL_DOWN>;
				nvidia,tristate = <TEGRA_PIN_DISABLE>;
			};

			pg0 {
				nvidia,pins = "pg0";
				nvidia,function = "safe";
				nvidia,enable-input = <TEGRA_PIN_DISABLE>;
				nvidia,pull = <TEGRA_PIN_PULL_NONE>;
				nvidia,tristate = <TEGRA_PIN_DISABLE>;
			};

			pg1 {
				nvidia,pins = "pg1";
				nvidia,function = "safe";
				nvidia,enable-input = <TEGRA_PIN_DISABLE>;
				nvidia,pull = <TEGRA_PIN_PULL_NONE>;
				nvidia,tristate = <TEGRA_PIN_DISABLE>;
			};

			ph2 {
				nvidia,pins = "ph2";
				nvidia,function = "safe";
				nvidia,enable-input = <TEGRA_PIN_DISABLE>;
				nvidia,pull = <TEGRA_PIN_PULL_NONE>;
				nvidia,tristate = <TEGRA_PIN_DISABLE>;
			};

			ph3 {
				nvidia,pins = "ph3";
				nvidia,function = "safe";
				nvidia,enable-input = <TEGRA_PIN_DISABLE>;
				nvidia,pull = <TEGRA_PIN_PULL_NONE>;
				nvidia,tristate = <TEGRA_PIN_ENABLE>;
			};

			ph4 {
				nvidia,pins = "ph4";
				nvidia,function = "safe";
				nvidia,enable-input = <TEGRA_PIN_ENABLE>;
				nvidia,pull = <TEGRA_PIN_PULL_UP>;
				nvidia,tristate = <TEGRA_PIN_DISABLE>;
			};

			ph5 {
				nvidia,pins = "ph5";
				nvidia,function = "safe";
				nvidia,enable-input = <TEGRA_PIN_DISABLE>;
				nvidia,pull = <TEGRA_PIN_PULL_NONE>;
				nvidia,tristate = <TEGRA_PIN_ENABLE>;
			};

			ph6 {
				nvidia,pins = "ph6";
				nvidia,function = "safe";
				nvidia,enable-input = <TEGRA_PIN_ENABLE>;
				nvidia,pull = <TEGRA_PIN_PULL_UP>;
				nvidia,tristate = <TEGRA_PIN_ENABLE>;
			};

			pg2 {
				nvidia,pins = "pg2";
				nvidia,function = "safe";
				nvidia,enable-input = <TEGRA_PIN_ENABLE>;
				nvidia,pull = <TEGRA_PIN_PULL_DOWN>;
				nvidia,tristate = <TEGRA_PIN_ENABLE>;
			};

			pg3 {
				nvidia,pins = "pg3";
				nvidia,function = "safe";
				nvidia,enable-input = <TEGRA_PIN_ENABLE>;
				nvidia,pull = <TEGRA_PIN_PULL_DOWN>;
				nvidia,tristate = <TEGRA_PIN_ENABLE>;
			};

			pk1 {
				nvidia,pins = "pk1";
				nvidia,function = "safe";
				nvidia,enable-input = <TEGRA_PIN_DISABLE>;
				nvidia,pull = <TEGRA_PIN_PULL_NONE>;
				nvidia,tristate = <TEGRA_PIN_DISABLE>;
			};

			pj0 {
				nvidia,pins = "pj0";
				nvidia,function = "safe";
				nvidia,enable-input = <TEGRA_PIN_ENABLE>;
				nvidia,pull = <TEGRA_PIN_PULL_UP>;
				nvidia,tristate = <TEGRA_PIN_ENABLE>;
			};

			pj2 {
				nvidia,pins = "pj2";
				nvidia,function = "safe";
				nvidia,enable-input = <TEGRA_PIN_ENABLE>;
				nvidia,pull = <TEGRA_PIN_PULL_UP>;
				nvidia,tristate = <TEGRA_PIN_ENABLE>;
			};

			pk3 {
				nvidia,pins = "pk3";
				nvidia,function = "safe";
				nvidia,enable-input = <TEGRA_PIN_ENABLE>;
				nvidia,pull = <TEGRA_PIN_PULL_UP>;
				nvidia,tristate = <TEGRA_PIN_ENABLE>;
			};

			pk4 {
				nvidia,pins = "pk4";
				nvidia,function = "safe";
				nvidia,enable-input = <TEGRA_PIN_DISABLE>;
				nvidia,pull = <TEGRA_PIN_PULL_NONE>;
				nvidia,tristate = <TEGRA_PIN_DISABLE>;
			};

			pk2 {
				nvidia,pins = "pk2";
				nvidia,function = "safe";
				nvidia,enable-input = <TEGRA_PIN_ENABLE>;
				nvidia,pull = <TEGRA_PIN_PULL_UP>;
				nvidia,tristate = <TEGRA_PIN_DISABLE>;
			};

			pi6 {
				nvidia,pins = "pi6";
				nvidia,function = "safe";
				nvidia,enable-input = <TEGRA_PIN_ENABLE>;
				nvidia,pull = <TEGRA_PIN_PULL_UP>;
				nvidia,tristate = <TEGRA_PIN_DISABLE>;
			};

			pi2 {
				nvidia,pins = "pi2";
				nvidia,function = "safe";
				nvidia,enable-input = <TEGRA_PIN_DISABLE>;
				nvidia,pull = <TEGRA_PIN_PULL_NONE>;
				nvidia,tristate = <TEGRA_PIN_ENABLE>;
			};

			pi5 {
				nvidia,pins = "pi5";
				nvidia,function = "safe";
				nvidia,enable-input = <TEGRA_PIN_ENABLE>;
				nvidia,pull = <TEGRA_PIN_PULL_UP>;
				nvidia,tristate = <TEGRA_PIN_ENABLE>;
			};

			pi4 {
				nvidia,pins = "pi4";
				nvidia,function = "safe";
				nvidia,enable-input = <TEGRA_PIN_DISABLE>;
				nvidia,pull = <TEGRA_PIN_PULL_NONE>;
				nvidia,tristate = <TEGRA_PIN_ENABLE>;
			};

			pc7 {
				nvidia,pins = "pc7";
				nvidia,function = "safe";
				nvidia,enable-input = <TEGRA_PIN_ENABLE>;
				nvidia,pull = <TEGRA_PIN_PULL_UP>;
				nvidia,tristate = <TEGRA_PIN_ENABLE>;
			};

			pi0 {
				nvidia,pins = "pi0";
				nvidia,function = "safe";
				nvidia,enable-input = <TEGRA_PIN_DISABLE>;
				nvidia,pull = <TEGRA_PIN_PULL_NONE>;
				nvidia,tristate = <TEGRA_PIN_ENABLE>;
			};

			pff2 {
				nvidia,pins = "pff2";
				nvidia,function = "safe";
				nvidia,enable-input = <TEGRA_PIN_ENABLE>;
				nvidia,pull = <TEGRA_PIN_PULL_UP>;
				nvidia,tristate = <TEGRA_PIN_ENABLE>;
			};

			clk2_req_pcc5 {
				nvidia,pins = "clk2_req_pcc5";
				nvidia,function = "safe";
				nvidia,enable-input = <TEGRA_PIN_DISABLE>;
				nvidia,pull = <TEGRA_PIN_PULL_NONE>;
				nvidia,tristate = <TEGRA_PIN_ENABLE>;
			};

			kb_col0_pq0 {
				nvidia,pins = "kb_col0_pq0";
				nvidia,function = "safe";
				nvidia,enable-input = <TEGRA_PIN_ENABLE>;
				nvidia,pull = <TEGRA_PIN_PULL_UP>;
				nvidia,tristate = <TEGRA_PIN_DISABLE>;
			};

			kb_col1_pq1 {
				nvidia,pins = "kb_col1_pq1";
				nvidia,function = "safe";
				nvidia,enable-input = <TEGRA_PIN_ENABLE>;
				nvidia,pull = <TEGRA_PIN_PULL_NONE>;
				nvidia,tristate = <TEGRA_PIN_ENABLE>;
			};

			kb_col2_pq2 {
				nvidia,pins = "kb_col2_pq2";
				nvidia,function = "safe";
				nvidia,enable-input = <TEGRA_PIN_ENABLE>;
				nvidia,pull = <TEGRA_PIN_PULL_UP>;
				nvidia,tristate = <TEGRA_PIN_ENABLE>;
			};

			kb_col5_pq5 {
				nvidia,pins = "kb_col5_pq5";
				nvidia,function = "safe";
				nvidia,enable-input = <TEGRA_PIN_ENABLE>;
				nvidia,pull = <TEGRA_PIN_PULL_UP>;
				nvidia,tristate = <TEGRA_PIN_DISABLE>;
			};

			kb_col6_pq6 {
				nvidia,pins = "kb_col6_pq6";
				nvidia,function = "safe";
				nvidia,enable-input = <TEGRA_PIN_ENABLE>;
				nvidia,pull = <TEGRA_PIN_PULL_UP>;
				nvidia,tristate = <TEGRA_PIN_ENABLE>;
			};

			kb_col7_pq7 {
				nvidia,pins = "kb_col7_pq7";
				nvidia,function = "safe";
				nvidia,enable-input = <TEGRA_PIN_ENABLE>;
				nvidia,pull = <TEGRA_PIN_PULL_UP>;
				nvidia,tristate = <TEGRA_PIN_ENABLE>;
			};

			kb_row0_pr0 {
				nvidia,pins = "kb_row0_pr0";
				nvidia,function = "safe";
				nvidia,enable-input = <TEGRA_PIN_DISABLE>;
				nvidia,pull = <TEGRA_PIN_PULL_NONE>;
				nvidia,tristate = <TEGRA_PIN_DISABLE>;
			};

			kb_row1_pr1 {
				nvidia,pins = "kb_row1_pr1";
				nvidia,function = "safe";
				nvidia,enable-input = <TEGRA_PIN_DISABLE>;
				nvidia,pull = <TEGRA_PIN_PULL_NONE>;
				nvidia,tristate = <TEGRA_PIN_ENABLE>;
			};

			kb_row11_ps3 {
				nvidia,pins = "kb_row11_ps3";
				nvidia,function = "safe";
				nvidia,enable-input = <TEGRA_PIN_DISABLE>;
				nvidia,pull = <TEGRA_PIN_PULL_NONE>;
				nvidia,tristate = <TEGRA_PIN_ENABLE>;
			};

			kb_row12_ps4 {
				nvidia,pins = "kb_row12_ps4";
				nvidia,function = "safe";
				nvidia,enable-input = <TEGRA_PIN_DISABLE>;
				nvidia,pull = <TEGRA_PIN_PULL_NONE>;
				nvidia,tristate = <TEGRA_PIN_ENABLE>;
			};

			kb_row13_ps5 {
				nvidia,pins = "kb_row13_ps5";
				nvidia,function = "safe";
				nvidia,enable-input = <TEGRA_PIN_ENABLE>;
				nvidia,pull = <TEGRA_PIN_PULL_UP>;
				nvidia,tristate = <TEGRA_PIN_DISABLE>;
			};

			kb_row14_ps6 {
				nvidia,pins = "kb_row14_ps6";
				nvidia,function = "safe";
				nvidia,enable-input = <TEGRA_PIN_DISABLE>;
				nvidia,pull = <TEGRA_PIN_PULL_NONE>;
				nvidia,tristate = <TEGRA_PIN_ENABLE>;
			};

			kb_row16_pt0 {
				nvidia,pins = "kb_row16_pt0";
				nvidia,function = "safe";
				nvidia,enable-input = <TEGRA_PIN_DISABLE>;
				nvidia,pull = <TEGRA_PIN_PULL_NONE>;
				nvidia,tristate = <TEGRA_PIN_DISABLE>;
			};

			kb_row17_pt1 {
				nvidia,pins = "kb_row17_pt1";
				nvidia,function = "safe";
				nvidia,enable-input = <TEGRA_PIN_DISABLE>;
				nvidia,pull = <TEGRA_PIN_PULL_NONE>;
				nvidia,tristate = <TEGRA_PIN_DISABLE>;
			};

			kb_row2_pr2 {
				nvidia,pins = "kb_row2_pr2";
				nvidia,function = "safe";
				nvidia,enable-input = <TEGRA_PIN_DISABLE>;
				nvidia,pull = <TEGRA_PIN_PULL_NONE>;
				nvidia,tristate = <TEGRA_PIN_DISABLE>;
			};

			kb_row4_pr4 {
				nvidia,pins = "kb_row4_pr4";
				nvidia,function = "safe";
				nvidia,enable-input = <TEGRA_PIN_ENABLE>;
				nvidia,pull = <TEGRA_PIN_PULL_UP>;
				nvidia,tristate = <TEGRA_PIN_ENABLE>;
			};

			kb_row5_pr5 {
				nvidia,pins = "kb_row5_pr5";
				nvidia,function = "safe";
				nvidia,enable-input = <TEGRA_PIN_DISABLE>;
				nvidia,pull = <TEGRA_PIN_PULL_NONE>;
				nvidia,tristate = <TEGRA_PIN_ENABLE>;
			};

			kb_row7_pr7 {
				nvidia,pins = "kb_row7_pr7";
				nvidia,function = "safe";
				nvidia,enable-input = <TEGRA_PIN_ENABLE>;
				nvidia,pull = <TEGRA_PIN_PULL_UP>;
				nvidia,tristate = <TEGRA_PIN_DISABLE>;
			};

			kb_row8_ps0 {
				nvidia,pins = "kb_row8_ps0";
				nvidia,function = "safe";
				nvidia,enable-input = <TEGRA_PIN_ENABLE>;
				nvidia,pull = <TEGRA_PIN_PULL_UP>;
				nvidia,tristate = <TEGRA_PIN_ENABLE>;
			};

			clk3_req_pee1 {
				nvidia,pins = "clk3_req_pee1";
				nvidia,function = "safe";
				nvidia,enable-input = <TEGRA_PIN_DISABLE>;
				nvidia,pull = <TEGRA_PIN_PULL_NONE>;
				nvidia,tristate = <TEGRA_PIN_ENABLE>;
			};

			pu0 {
				nvidia,pins = "pu0";
				nvidia,function = "safe";
				nvidia,enable-input = <TEGRA_PIN_DISABLE>;
				nvidia,pull = <TEGRA_PIN_PULL_NONE>;
				nvidia,tristate = <TEGRA_PIN_ENABLE>;
			};

			pu1 {
				nvidia,pins = "pu1";
				nvidia,function = "safe";
				nvidia,enable-input = <TEGRA_PIN_ENABLE>;
				nvidia,pull = <TEGRA_PIN_PULL_DOWN>;
				nvidia,tristate = <TEGRA_PIN_DISABLE>;
			};

			pu2 {
				nvidia,pins = "pu2";
				nvidia,function = "safe";
				nvidia,enable-input = <TEGRA_PIN_ENABLE>;
				nvidia,pull = <TEGRA_PIN_PULL_DOWN>;
				nvidia,tristate = <TEGRA_PIN_ENABLE>;
			};

			pu3 {
				nvidia,pins = "pu3";
				nvidia,function = "safe";
				nvidia,enable-input = <TEGRA_PIN_DISABLE>;
				nvidia,pull = <TEGRA_PIN_PULL_NONE>;
				nvidia,tristate = <TEGRA_PIN_ENABLE>;
			};

			pu4 {
				nvidia,pins = "pu4";
				nvidia,function = "safe";
				nvidia,enable-input = <TEGRA_PIN_DISABLE>;
				nvidia,pull = <TEGRA_PIN_PULL_NONE>;
				nvidia,tristate = <TEGRA_PIN_ENABLE>;
			};

			pu5 {
				nvidia,pins = "pu5";
				nvidia,function = "safe";
				nvidia,enable-input = <TEGRA_PIN_ENABLE>;
				nvidia,pull = <TEGRA_PIN_PULL_UP>;
				nvidia,tristate = <TEGRA_PIN_DISABLE>;
			};

			pu6 {
				nvidia,pins = "pu6";
				nvidia,function = "safe";
				nvidia,enable-input = <TEGRA_PIN_ENABLE>;
				nvidia,pull = <TEGRA_PIN_PULL_UP>;
				nvidia,tristate = <TEGRA_PIN_ENABLE>;
			};

			hdmi_int_pn7 {
				nvidia,pins = "hdmi_int_pn7";
				nvidia,function = "safe";
				nvidia,enable-input = <TEGRA_PIN_ENABLE>;
				nvidia,pull = <TEGRA_PIN_PULL_DOWN>;
				nvidia,tristate = <TEGRA_PIN_DISABLE>;
			};

			spdif_in_pk6 {
				nvidia,pins = "spdif_in_pk6";
				nvidia,function = "safe";
				nvidia,enable-input = <TEGRA_PIN_DISABLE>;
				nvidia,pull = <TEGRA_PIN_PULL_NONE>;
				nvidia,tristate = <TEGRA_PIN_DISABLE>;
			};

			ulpi_data3_po4 {
				nvidia,pins = "ulpi_data3_po4";
				nvidia,function = "safe";
				nvidia,enable-input = <TEGRA_PIN_ENABLE>;
				nvidia,pull = <TEGRA_PIN_PULL_UP>;
				nvidia,tristate = <TEGRA_PIN_DISABLE>;
			};

			dap3_sclk_pp3 {
				nvidia,pins = "dap3_sclk_pp3";
				nvidia,function = "safe";
				nvidia,enable-input = <TEGRA_PIN_DISABLE>;
				nvidia,pull = <TEGRA_PIN_PULL_DOWN>;
				nvidia,tristate = <TEGRA_PIN_ENABLE>;
			};

			ph7 {
				nvidia,pins = "ph7";
				nvidia,function = "safe";
				nvidia,enable-input = <TEGRA_PIN_DISABLE>;
				nvidia,pull = <TEGRA_PIN_PULL_DOWN>;
				nvidia,tristate = <TEGRA_PIN_ENABLE>;
			};

			ph0 {
				nvidia,pins = "ph0";
				nvidia,function = "pwm0";
				nvidia,enable-input = <TEGRA_PIN_DISABLE>;
				nvidia,pull = <TEGRA_PIN_PULL_DOWN>;
				nvidia,tristate = <TEGRA_PIN_DISABLE>;
			};

			pi1 {
				nvidia,pins = "pi1";
				nvidia,function = "safe";
				nvidia,enable-input = <TEGRA_PIN_DISABLE>;
				nvidia,pull = <TEGRA_PIN_PULL_DOWN>;
				nvidia,tristate = <TEGRA_PIN_ENABLE>;
			};

			pi7 {
				nvidia,pins = "pi7";
				nvidia,function = "safe";
				nvidia,enable-input = <TEGRA_PIN_DISABLE>;
				nvidia,pull = <TEGRA_PIN_PULL_DOWN>;
				nvidia,tristate = <TEGRA_PIN_DISABLE>;
			};

			sdmmc1_wp_n_pv3 {
				nvidia,pins = "sdmmc1_wp_n_pv3";
				nvidia,function = "safe";
				nvidia,enable-input = <TEGRA_PIN_DISABLE>;
				nvidia,pull = <TEGRA_PIN_PULL_DOWN>;
				nvidia,tristate = <TEGRA_PIN_ENABLE>;
			};

			kb_col3_pq3 {
				nvidia,pins = "kb_col3_pq3";
				nvidia,function = "safe";
				nvidia,enable-input = <TEGRA_PIN_DISABLE>;
				nvidia,pull = <TEGRA_PIN_PULL_DOWN>;
				nvidia,tristate = <TEGRA_PIN_ENABLE>;
			};

			owr {
				nvidia,pins = "owr";
				nvidia,function = "safe";
				nvidia,enable-input = <TEGRA_PIN_DISABLE>;
				nvidia,pull = <TEGRA_PIN_PULL_DOWN>;
				nvidia,tristate = <TEGRA_PIN_ENABLE>;
			};

			ulpi_data4_po5 {
				nvidia,pins = "ulpi_data4_po5";
				nvidia,function = "safe";
				nvidia,enable-input = <TEGRA_PIN_DISABLE>;
				nvidia,pull = <TEGRA_PIN_PULL_UP>;
				nvidia,tristate = <TEGRA_PIN_ENABLE>;
			};

			ulpi_data5_po6 {
				nvidia,pins = "ulpi_data5_po6";
				nvidia,function = "safe";
				nvidia,enable-input = <TEGRA_PIN_DISABLE>;
				nvidia,pull = <TEGRA_PIN_PULL_NONE>;
				nvidia,tristate = <TEGRA_PIN_ENABLE>;
			};

			ulpi_data6_po7 {
				nvidia,pins = "ulpi_data6_po7";
				nvidia,function = "safe";
				nvidia,enable-input = <TEGRA_PIN_DISABLE>;
				nvidia,pull = <TEGRA_PIN_PULL_UP>;
				nvidia,tristate = <TEGRA_PIN_ENABLE>;
			};

			ulpi_data7_po0 {
				nvidia,pins = "ulpi_data7_po0";
				nvidia,function = "safe";
				nvidia,enable-input = <TEGRA_PIN_DISABLE>;
				nvidia,pull = <TEGRA_PIN_PULL_UP>;
				nvidia,tristate = <TEGRA_PIN_ENABLE>;
			};

			spdif_out_pk5 {
				nvidia,pins = "spdif_out_pk5";
				nvidia,function = "safe";
				nvidia,enable-input = <TEGRA_PIN_DISABLE>;
				nvidia,pull = <TEGRA_PIN_PULL_NONE>;
				nvidia,tristate = <TEGRA_PIN_ENABLE>;
			};

			drive_sdio1 {
				nvidia,pins = "drive_sdio1";
				nvidia,high-speed-mode = <TEGRA_PIN_ENABLE>;
				nvidia,schmitt = <TEGRA_PIN_DISABLE>;
				nvidia,pull-down-strength = <32>;
				nvidia,pull-up-strength = <42>;
				nvidia,slew-rate-rising = <TEGRA_PIN_SLEW_RATE_FASTEST>;
				nvidia,slew-rate-falling = <TEGRA_PIN_SLEW_RATE_FASTEST>;
			};

			drive_sdio3 {
				nvidia,pins = "drive_sdio3";
				nvidia,high-speed-mode = <TEGRA_PIN_ENABLE>;
				nvidia,schmitt = <TEGRA_PIN_DISABLE>;
				nvidia,pull-down-strength = <22>;
				nvidia,pull-up-strength = <36>;
				nvidia,slew-rate-rising = <TEGRA_PIN_SLEW_RATE_FASTEST>;
				nvidia,slew-rate-falling = <TEGRA_PIN_SLEW_RATE_FASTEST>;
			};

			drive_gma {
				nvidia,pins = "drive_gma";
				nvidia,high-speed-mode = <TEGRA_PIN_ENABLE>;
				nvidia,schmitt = <TEGRA_PIN_DISABLE>;
				nvidia,low-power-mode = <TEGRA_PIN_LP_DRIVE_DIV_1>;
				nvidia,pull-down-strength = <2>;
				nvidia,pull-up-strength = <1>;
				nvidia,slew-rate-rising = <TEGRA_PIN_SLEW_RATE_FASTEST>;
				nvidia,slew-rate-falling = <TEGRA_PIN_SLEW_RATE_FASTEST>;
				nvidia,drive-type = <1>;
			};
		};
	};

	host1x {
		vi {
			avdd_dsi_csi-supply = <&avdd_dsi_csi>;

			#address-cells = <1>;
			#size-cells = <0>;

			port@0 {
				reg = <0>;

				#address-cells = <1>;
				#size-cells = <0>;

				csi_ab_ep: endpoint@0 {
					reg = <0>;
				};
			};

			port@1 {
				reg = <1>;

				#address-cells = <1>;
				#size-cells = <0>;

				csi_cd_ep: endpoint@0 {
					reg = <0>;
				};
			};

			port@2 {
				reg = <2>;

				#address-cells = <1>;
				#size-cells = <0>;

				csi_e_ep: endpoint@0 {
					reg = <0>;
				};
			};
		};

		dc@54200000 {
			avdd_hdmi-supply = <&vdd_3v3_hdmi>;
			avdd_hdmi_pll-supply = <&vdd_hdmi_pll>;
			avdd_dsi_csi-supply = <&avdd_dsi_csi>;
			nvidia,fb-bpp = <32>;
			nvidia,emc-clk-rate = <204000000>;
			nvidia,low-v-win = <2>;

			nvidia,dc-flags = <TEGRA_DC_FLAG_ENABLED>;
		};
		dc@54240000 {
			avdd_hdmi-supply = <&vdd_3v3_hdmi>;
			avdd_hdmi_pll-supply = <&vdd_hdmi_pll>;
			avdd_dsi_csi-supply = <&avdd_dsi_csi>;
			nvidia,fb-bpp = <32>;
			nvidia,emc-clk-rate = <300000000>;

			nvidia,dc-flags = <TEGRA_DC_FLAG_ENABLED>;
		};
		hdmi {
			status = "disabled";

			/* I2C bused for DDC */
			nvidia,ddc-i2c-bus = <&i2c4>;

			/* GPIO used for hotplug detection
			 * WARNING: the flags given here are ignored.
			 * hdmi-display/disp-default-out/nvidia,out-flags
			 * must be used instead */
			nvidia,hpd-gpio = <&gpio TEGRA_GPIO(N, 7) GPIO_ACTIVE_HIGH>;

			/* Default display definition */
			hdmi-display {
				disp-default-out {
					nvidia,out-type = <TEGRA_DC_OUT_HDMI>;
					nvidia,out-flags = <TEGRA_DC_OUT_HOTPLUG_HIGH>;
					nvidia,out-parent-clk = "pll_d2";
					nvidia,out-max-pixclk = <3367>; /* KHZ2PICOS(297000) */
					nvidia,out-align = <TEGRA_DC_ALIGN_MSB>;
					nvidia,out-order = <TEGRA_DC_ORDER_RED_BLUE>;
					nvidia,out-xres = <1920>;
					nvidia,out-yres = <1080>;
				};
				/* At least one mode MUST be defined for the driver to work */
				display-timings {
					1080p {
						clock-frequency = <148500000>;
						nvidia,h-ref-to-sync = <1>;
						nvidia,v-ref-to-sync = <1>;
						hsync-len = <44>;
						vsync-len = <5>;
						hback-porch = <148>;
						vback-porch = <36>;
						hactive = <1920>;
						vactive = <1080>;
						hfront-porch = <88>;
						vfront-porch = <4>;
					};
				};
			};
		};
	};

	pcie-controller {
		hvdd-pex-supply = <&vdd_3v3_lp0>;
		avddio-pex-supply = <&vdd_1v05_run>;
		avdd-pll-erefe-supply = <&avdd_1v05_run>;
	};

	hier-ictlr@60004800 {
		status = "okay";
	};

	/* tegra124-soc.dtsi enable all the i2c bus and HDMI, disable them again here
	   because not all baseboards will use them. */
	i2c@7000c000 {
		status = "disabled";
	};

	i2c@7000c400 {
		status = "disabled";
	};

	i2c@7000c500 {
		status = "disabled";
		pull-ups-supply = <&avdd_1v8_cam_run>;
	};

	i2c@7000c700 {
		status = "disabled";
	};

	i2c@7000d000 {
		status = "okay";

		/* Required for PMIC access via i2c during shutdown: */
		nvidia,bit-banging-xfer-after-shutdown;

		pmic: pmic@40 {
			compatible = "ams,as3722";
			reg = <0x40>;
			interrupts = <0 86 IRQ_TYPE_LEVEL_HIGH>;

			#interrupt-cells = <2>;
			interrupt-controller;

			gpio-controller;
			#gpio-cells = <2>;

			#address-cells = <1>;
			#size-cells = <0>;

			ams,major-rev = <1>;
			ams,minor-rev = <2>;
			ams,system-power-controller;
			ams,enable-ac-ok-power-on;
			ams,extcon-name = "as3722-extcon";
			ams,enable-adc1-continuous-mode;
			ams,enable-low-voltage-range;
			ams,adc-channel = <12>;
			ams,hi-threshold = <256>;
			ams,low-threshold = <128>;
			ams,enable-clock32k-out;
			ams,backup-battery-chargable;
			ams,battery-backup-charge-current = <AS3722_BBCCUR_400UA>;
			ams,battery-backup-enable-bypass;
			ams,battery-backup-charge-mode = <AS3722_BBCMODE_ACT_STBY_OFF>;

			pinctrl-names = "default";
			pinctrl-0 = <&as3722_default>;

			as3722_input: input@0 {
				status = "okay";

				compatible = "ams,as3722-input";
				reg = <0>;
			};

			as3722_default: pinmux@0 {
				gpio0 {
					pins = "gpio0";
					function = "gpio";
					output-low;
				};

				gpio1_2_4 {
					pins = "gpio1", "gpio2", "gpio4";
					function = "gpio";
					bias-pull-down;
					output-high;
				};

				gpio7 {
					pins = "gpio7";
					function = "gpio";
					bias-pull-up;
					output-high;
				};

				gpio3_6 {
					pins = "gpio3", "gpio6";
					function = "gpio";
					bias-high-impedance;
				};
			};

			regulators {
				vsup-sd2-supply = <&vdd_5v0_sys>;
				vsup-sd3-supply = <&vdd_5v0_sys>;
				vsup-sd4-supply = <&vdd_5v0_sys>;
				vsup-sd5-supply = <&vdd_5v0_sys>;
				vin-ldo0-supply = <&vdd_1v35_lp0>;
				vin-ldo1-6-supply = <&vdd_3v3_run>;
				vin-ldo2-5-7-supply = <&vddio_1v8>;
				vin-ldo3-4-supply = <&vdd_3v3_sys>;
				vin-ldo9-10-supply = <&vdd_5v0_sys>;
				vin-ldo11-supply = <&vdd_3v3_run>;

				vdd_cpu: sd0 {
					regulator-name = "+VDD_CPU_AP";
					regulator-min-microvolt = <650000>;
					regulator-max-microvolt = <1400000>;
					regulator-min-microamp = <3500000>;
					regulator-max-microamp = <3500000>;
					regulator-always-on;
					regulator-boot-on;
					ams,ext-control = <AS3722_EXT_CONTROL_ENABLE2>;

					consumers {
						cpu {
							regulator-consumer-supply = "vdd_cpu";
						};
					};
				};

				sd1 {
					regulator-name = "+VDD_CORE";
					regulator-min-microvolt = <700000>;
					regulator-max-microvolt = <1350000>;
					regulator-min-microamp = <3500000>;
					regulator-max-microamp = <3500000>;
					regulator-always-on;
					regulator-boot-on;
					ams,ext-control = <AS3722_EXT_CONTROL_ENABLE1>;

					consumers {
						core {
							regulator-consumer-supply = "vdd_core";
						};
					};
				};

				vdd_1v35_lp0: sd2 {
					 regulator-name = "+1V35_LP0(sd2)";
					 regulator-always-on;
					 regulator-boot-on;
				 };

				sd3 {
					 regulator-name = "+1V35_LP0(sd3)";
					 regulator-always-on;
					 regulator-boot-on;
				 };

				vdd_1v05_run: sd4 {
					regulator-name = "+1V05_RUN";
					regulator-min-microvolt = <1050000>;
					regulator-max-microvolt = <1050000>;
					ams,ext-control = <AS3722_EXT_CONTROL_ENABLE1>;
				};

				vddio_1v8: sd5 {
					regulator-name = "+1V8_VDDIO";
					regulator-min-microvolt = <1800000>;
					regulator-max-microvolt = <1800000>;
					regulator-always-on;
					regulator-boot-on;

					consumers {
						temp_sensor {
							regulator-consumer-device = "4-004c";
							regulator-consumer-supply = "vdd";
						};
					};
				};

				vdd_gpu: sd6 {
					regulator-name = "+VDD_GPU_AP";
					regulator-min-microvolt = <650000>;
					regulator-max-microvolt = <1200000>;
					regulator-min-microamp = <3500000>;
					regulator-max-microamp = <3500000>;
					regulator-init-microvolt = <1000000>;
					regulator-boot-on;
					/* CHECK in mainline also regulator-always-on */

					consumers {
						gpu {
							regulator-consumer-supply = "vdd_gpu";
						};
						gpu_simon {
							regulator-consumer-supply = "vdd_gpu_simon";
						};
					};
				};

				avdd_1v05_run: ldo0 {
					regulator-name = "+1V05_RUN_AVDD";
					regulator-min-microvolt = <1050000>;
					regulator-max-microvolt = <1050000>;
					regulator-always-on;
					regulator-boot-on;
					ams,ext-control = <AS3722_EXT_CONTROL_ENABLE1>;
				};

				avdd_1v8_cam_run: ldo1 {
					regulator-name = "+1V8_RUN_CAM";
					regulator-min-microvolt = <1800000>;
					regulator-max-microvolt = <1800000>;
				};

				avdd_dsi_csi: ldo2 {
					regulator-name = "+1V2_GEN_AVDD";
					regulator-min-microvolt = <1200000>;
					regulator-max-microvolt = <1200000>;
					regulator-boot-on;
					/* CHECK in mainline also regulator-always-on */
					consumers {
						/* Second vi has no DT entry, provide reg supply here */
						c1 {
							regulator-consumer-supply = "avdd_dsi_csi";
							regulator-consumer-device = "vi.1";
						};
					};
				};

				ldo3 {
					regulator-name = "+1V05_LDO_VDD_RTC";
					regulator-min-microvolt = <1000000>;
					regulator-max-microvolt = <1000000>;
					regulator-always-on;
					regulator-boot-on;
					ams,enable-tracking;
					ams,disable-tracking-suspend;
				};

				vddio_sdmmc3: ldo6 {
					regulator-name = "+VDDIO_SDMMC3";
					regulator-min-microvolt = <1800000>;
					regulator-max-microvolt = <3300000>;
				};

				vpp_fuse: ldo11 {
					regulator-name = "+1V8_RUN_VPP_FUSE";
					regulator-min-microvolt = <1800000>;
					regulator-max-microvolt = <1800000>;
				};

			};
		};

		com_temperature_sensor: temperature-sensor@4c {
			compatible = "tmp451";
			reg = <0x4c>;
			interrupt-parent = <&gpio>;
			interrupts = <TEGRA_GPIO(I, 6) IRQ_TYPE_LEVEL_LOW>;
			vcc-supply = <&vddio_1v8>;

			#thermal-sensor-cells = <1>;
		};
	};

	i2c@7000d100 {
		status = "disabled";
	};

	spi@7000d400 {
		status = "disabled";
	};

	spi@7000d600 {
		status = "disabled";
	};

	spi@7000d800 {
		status = "disabled";
	};

	spi@7000da00 {
		status = "disabled";
	};

	spi@7000dc00 {
		status = "disabled";
	};

	spi@7000de00 {
		status = "disabled";
	};

	rtc {
		status = "okay";
	};

	pmc { /* The PMC is missing an address */
		status = "okay";
		nvidia,invert-interrupt;
		nvidia,suspend-mode = <0>;
		nvidia,cpu-pwr-good-time = <500>;
		nvidia,cpu-pwr-off-time = <300>;
		nvidia,core-pwr-good-time = <3845 3845>;
		nvidia,core-pwr-off-time = <2000>;
		nvidia,core-power-req-active-high;
		nvidia,sys-clock-req-active-high;
	};

	emc: memory-controller@7001b000 {
		compatible = "nvidia,tegra12-emc";
		reg = <0x0 0x7001b000 0x0 0x800>;
		#address-cells = <1>;
		#size-cells = <0>;
		nvidia,use-ram-code;
	};

	sata@0x70020000 {
		nvidia,enable-sata-port;
		nvidia,sata-connector-type = <STANDARD_SATA>;
		avdd_sata_pll-supply =<&vdd_1v05_run>;
		avdd_sata-supply = <&vdd_1v05_run>;
		hvdd_sata-supply = <&vdd_3v3_lp0>;
		vddio_pex_sata-supply = <&vdd_1v05_run>;
	};

	efuse@7000f800 {
		vpp_fuse-supply = <&vpp_fuse>;
	};

	/* SD card */
	sdhci@700b0400 {
		cd-gpios = <&gpio TEGRA_GPIO(V, 2) GPIO_ACTIVE_LOW>;
		wp-gpios = <&gpio TEGRA_GPIO(Q, 4) GPIO_ACTIVE_HIGH>;
		bus-width = <4>;
		vddio_sdmmc-supply = <&vddio_sdmmc3>;

		#address-cells = <1>;
		#size-cells = <0>;
	};

	/* eMMC */
	sdhci@700b0600 {
		status = "okay";
		bus-width = <8>;
		built-in;

		tap-delay = <4>;
		trim-delay = <4>;
		ddr-clk-limit = <51000000>;
		max-clk-limit = <200000000>;
		calib-3v3-offsets = <0x0202>;
		calib-1v8-offsets = <0x0202>;
		mmc-ocr-mask = <0>;

		vddio_sdmmc-supply = <&vddio_1v8>;
		vddio_sd_slot-supply = <&vdd_3v3_run>;
	};

	tegra_ehci_0: usb@7d000000 {
		nvidia,phy-interface = <TEGRA_USB_PHY_INTF_UTMI>;
		nvidia,mode = <TEGRA_USB_OPMODE_HOST>;
		nvidia,id-det-type = <TEGRA_USB_PMU_ID>;
		nvidia,id-extcon-dev-name = "as3722-extcon";

		nvidia,hssync-start-delay = <0>;
		nvidia,elastic-limit = <16>;
		nvidia,idle-wait-delay = <17>;
		nvidia,term-range-adj = <6>;
		nvidia,xcvr-setup = <8>;
		nvidia,xcvr-lsfslew = <2>;
		nvidia,xcvr-lsrslew = <2>;
		nvidia,xcvr-setup-offset = <0>;
		nvidia,xcvr-use-fuses = <1>;

		avdd_usb-supply = <&vdd_3v3_lp0>;
		avdd_pll_utmip-supply = <&vddio_1v8>;
	};

	tegra_udc: udc@7d000000 {
		nvidia,port-otg;
		nvidia,phy-interface = <TEGRA_USB_PHY_INTF_UTMI>;
		nvidia,mode = <TEGRA_USB_OPMODE_DEVICE>;
		nvidia,id-det-type = <TEGRA_USB_PMU_ID>;
		nvidia,id-extcon-dev-name = "as3722-extcon";

		nvidia,hssync-start-delay = <0>;
		nvidia,elastic-limit = <16>;
		nvidia,idle-wait-delay = <17>;
		nvidia,term-range-adj = <6>;
		nvidia,xcvr-setup = <8>;
		nvidia,xcvr-lsfslew = <2>;
		nvidia,xcvr-lsrslew = <2>;
		nvidia,xcvr-setup-offset = <0>;
		nvidia,xcvr-use-fuses = <1>;

		avdd_usb-supply = <&vdd_3v3_lp0>;
		avdd_pll_utmip-supply = <&vddio_1v8>;
	};

	otg@7d000000 {
		nvidia,ehci-device = <&tegra_ehci_0>;
	};

	usb@7d004000 {
		nvidia,phy-interface = <TEGRA_USB_PHY_INTF_UTMI>;
		nvidia,mode = <TEGRA_USB_OPMODE_HOST>;

		nvidia,hssync-start-delay = <0>;
		nvidia,elastic-limit = <16>;
		nvidia,idle-wait-delay = <17>;
		nvidia,term-range-adj = <6>;
		nvidia,xcvr-setup = <8>;
		nvidia,xcvr-lsfslew = <2>;
		nvidia,xcvr-lsrslew = <2>;
		nvidia,xcvr-setup-offset = <0>;
		nvidia,xcvr-use-fuses = <1>;

		avdd_usb-supply = <&vdd_3v3_lp0>;
		avdd_pll_utmip-supply = <&vddio_1v8>;
	};

	usb@7d008000 {
		nvidia,phy-interface = <TEGRA_USB_PHY_INTF_UTMI>;
		nvidia,mode = <TEGRA_USB_OPMODE_HOST>;

		nvidia,hssync-start-delay = <0>;
		nvidia,elastic-limit = <16>;
		nvidia,idle-wait-delay = <17>;
		nvidia,term-range-adj = <6>;
		nvidia,xcvr-setup = <8>;
		nvidia,xcvr-lsfslew = <2>;
		nvidia,xcvr-lsrslew = <2>;
		nvidia,xcvr-setup-offset = <0>;
		nvidia,xcvr-use-fuses = <1>;

		avdd_usb-supply = <&vdd_3v3_lp0>;
		avdd_pll_utmip-supply = <&vddio_1v8>;
	};

	xusb@70090000 {
		hvdd_usb-supply = <&vdd_3v3_lp0>;
		avdd_pll_utmip-supply = <&vddio_1v8>;
		vddio_hsic-supply = <&avdd_dsi_csi>;
		avddio_usb-supply= <&avdd_1v05_run>;
	};

	regulators {
		compatible = "simple-bus";
		#address-cells = <1>;
		#size-cells = <0>;

		vdd_mux: regulator@0 {
			compatible = "regulator-fixed";
			reg = <0>;
			regulator-name = "+VDD_MUX";
			regulator-min-microvolt = <5000000>;
			regulator-max-microvolt = <5000000>;
			regulator-always-on;
			regulator-boot-on;
			vin-supply = <&vdd_5v0>;
		};

		vdd_5v0_sys: regulator@1 {
			compatible = "regulator-fixed";
			reg = <1>;
			regulator-name = "+5V_SYS";
			regulator-min-microvolt = <5000000>;
			regulator-max-microvolt = <5000000>;
			regulator-always-on;
			regulator-boot-on;
			vin-supply = <&vdd_mux>;
		};

		vdd_3v3_sys: regulator@2 {
			compatible = "regulator-fixed";
			reg = <2>;
			regulator-name = "+3V3_SYS";
			regulator-min-microvolt = <3300000>;
			regulator-max-microvolt = <3300000>;
			regulator-always-on;
			regulator-boot-on;
			vin-supply = <&vdd_3v3>;
		};

		vdd_3v3_run: regulator@3 {
			compatible = "regulator-fixed";
			reg = <3>;
			regulator-name = "+3V3_RUN";
			regulator-min-microvolt = <3300000>;
			regulator-max-microvolt = <3300000>;
			regulator-always-on;
			regulator-boot-on;
			gpio = <&pmic 1 GPIO_ACTIVE_HIGH>;
			enable-active-high;
			vin-supply = <&vdd_3v3_sys>;
		};

		vdd_3v3_hdmi: regulator@4 {
			compatible = "regulator-fixed";
			reg = <4>;
			regulator-name = "+3V3_AVDD_HDMI_AP_GATED";
			regulator-min-microvolt = <3300000>;
			regulator-max-microvolt = <3300000>;
			vin-supply = <&vdd_3v3_run>;
		};

		vdd_3v3_lp0: regulator@5 {
			compatible = "regulator-fixed";
			reg = <5>;
			regulator-name = "+3V3_LP0";
			regulator-min-microvolt = <3300000>;
			regulator-max-microvolt = <3300000>;
			regulator-always-on;
			regulator-boot-on;
			gpio = <&pmic 2 GPIO_ACTIVE_HIGH>;
			enable-active-high;
			vin-supply = <&vdd_3v3_sys>;
		};

		vdd_hdmi_pll: regulator@6 {
			compatible = "regulator-fixed";
			reg = <6>;
			regulator-name = "+1V05_RUN_AVDD_HDMI_PLL_AP_GATED";
			regulator-min-microvolt = <1050000>;
			regulator-max-microvolt = <1050000>;
			gpio = <&gpio TEGRA_GPIO(H, 7) GPIO_ACTIVE_LOW>;
			vin-supply = <&vdd_1v05_run>;
		};
	};

	cpu_fan: pwm-fan {
		compatible = "pwm-fan";
		status = "disabled";
		pwms = <&tegra_pwm 0 40000>;

		#cooling-cells = <2>;
		cooling-levels = <0>, <128>, <192>, <255>;
	};

	thermal-zones {
		com_thermal: com-thermal {
			polling-delay-passive = <250>;
			polling-delay = <1000>;

			thermal-sensors = <&com_temperature_sensor 0>;
		};

		cpu_thermal: cpu-thermal {
			polling-delay-passive = <250>;
			polling-delay = <1000>;

			thermal-sensors = <&com_temperature_sensor 1>;

			trips {
				cpu_alert0: cpu-alert0 {
					temperature = <25000>;
					hysteresis = <1000>;
					type = "active";
				};
				cpu_alert1: cpu-alert1 {
					temperature = <60000>;
					hysteresis = <1000>;
					type = "active";
				};
				cpu_alert2: cpu-alert2 {
					temperature = <80000>;
					hysteresis = <1000>;
					type = "active";
				};
				cpu_crit: cpu-crit {
					temperature = <95000>;
					hysteresis = <1000>;
					type = "critical";
				};
			};

			cooling-maps {
				map0 {
					trip = <&cpu_alert0>;
					cooling-device = <&cpu_fan 1 1>;
				};
				map1 {
					trip = <&cpu_alert1>;
					cooling-device = <&cpu_fan 1 2>;
				};
				map2 {
					trip = <&cpu_alert2>;
					cooling-device = <&cpu_fan 2 THERMAL_NO_LIMIT>;
				};

			};
		};
	};

	/* HACK driver for the power detection */
	power_detect {
		compatible = "nvidia,tegra124-power-detect";
		pwrdet_nand-supply = <&vddio_1v8>;
		pwrdet_uart-supply = <&vddio_1v8>;
		pwrdet_bb-supply = <&vddio_1v8>;
		pwrdet_audio-supply = <&vddio_1v8>;
		pwrdet_mipi-supply = <&avdd_dsi_csi>;
		pwrdet_cam-supply = <&avdd_1v8_cam_run>;
		pwrdet_pex_ctl-supply = <&vdd_1v05_run>;
		pwrdet_sdmmc1-supply = <&vddio_1v8>;
		pwrdet_sdmmc3-supply = <&vddio_sdmmc3>;
		pwrdet_sdmmc4-supply = <&vddio_1v8>;
		pwrdet_hv-supply = <&vdd_3v3_lp0>;
	};
};

/* Include the memory configs, these must be afterwards to
 * allow using the 'emc' label. */
#include "tegra124-meerkat-emc.dtsi"
